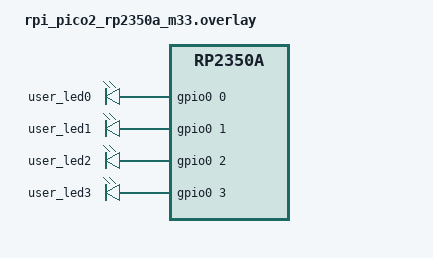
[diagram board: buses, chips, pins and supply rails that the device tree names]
/ {
	aliases {
		led0 = &user_led0;
		led1 = &user_led1;
		led2 = &user_led2;
		led3 = &user_led3;
	};

	leds {
		compatible = "gpio-leds";

		user_led0: user_led0 { gpios = <&gpio0 0 GPIO_ACTIVE_HIGH>; };
		user_led1: user_led1 { gpios = <&gpio0 1 GPIO_ACTIVE_HIGH>; };
		user_led2: user_led2 { gpios = <&gpio0 2 GPIO_ACTIVE_HIGH>; };
		user_led3: user_led3 { gpios = <&gpio0 3 GPIO_ACTIVE_HIGH>; };
	};
};
